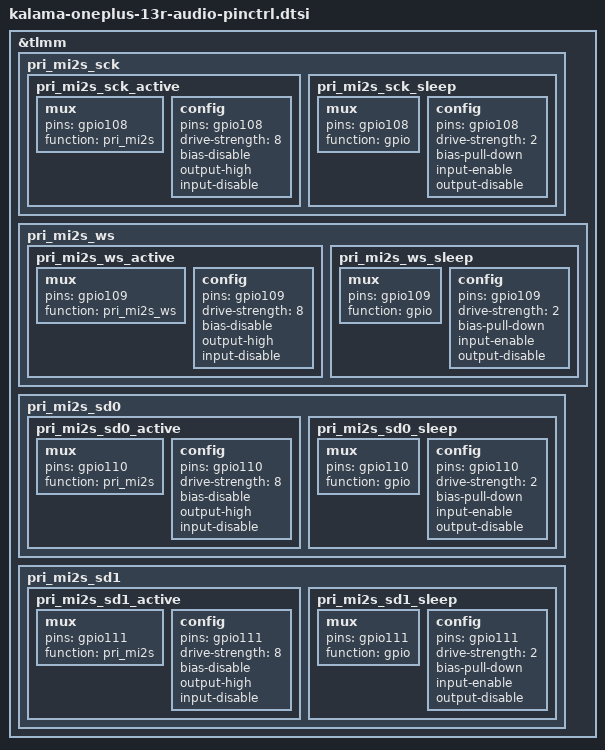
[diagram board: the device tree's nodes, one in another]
/*
 * Copyright (c) 2024, The LineageOS Project
 *
 * This program is free software; you can redistribute it and/or modify
 * it under the terms of the GNU General Public License version 2 and
 * only version 2 as published by the Free Software Foundation.
 *
 * This program is distributed in the hope that it will be useful,
 * but WITHOUT ANY WARRANTY; without even the implied warranty of
 * MERCHANTABILITY or FITNESS FOR A PARTICULAR PURPOSE.  See the
 * GNU General Public License for more details.
 */

&tlmm {
    pri_mi2s_sck {
        pri_mi2s_sck_active: pri_mi2s_sck_active {
            mux {
                pins = "gpio108";
                function = "pri_mi2s";
            };

            config {
                pins = "gpio108";
                drive-strength = <8>;
                bias-disable;
                output-high;
                input-disable;
            };
        };

        pri_mi2s_sck_sleep: pri_mi2s_sck_sleep {
            mux {
                pins = "gpio108";
                function = "gpio";
            };

            config {
                pins = "gpio108";
                drive-strength = <2>;
                bias-pull-down;
                input-enable;
                output-disable;
            };
        };
    };

    pri_mi2s_ws {
        pri_mi2s_ws_active: pri_mi2s_ws_active {
            mux {
                pins = "gpio109";
                function = "pri_mi2s_ws";
            };

            config {
                pins = "gpio109";
                drive-strength = <8>;
                bias-disable;
                output-high;
                input-disable;
            };
        };

        pri_mi2s_ws_sleep: pri_mi2s_ws_sleep {
            mux {
                pins = "gpio109";
                function = "gpio";
            };

            config {
                pins = "gpio109";
                drive-strength = <2>;
                bias-pull-down;
                input-enable;
                output-disable;
            };
        };
    };

    pri_mi2s_sd0 {
        pri_mi2s_sd0_active: pri_mi2s_sd0_active {
            mux {
                pins = "gpio110";
                function = "pri_mi2s";
            };

            config {
                pins = "gpio110";
                drive-strength = <8>;
                bias-disable;
                output-high;
                input-disable;
            };
        };

        pri_mi2s_sd0_sleep: pri_mi2s_sd0_sleep {
            mux {
                pins = "gpio110";
                function = "gpio";
            };

            config {
                pins = "gpio110";
                drive-strength = <2>;
                bias-pull-down;
                input-enable;
                output-disable;
            };
        };
    };

    pri_mi2s_sd1 {
        pri_mi2s_sd1_active: pri_mi2s_sd1_active {
            mux {
                pins = "gpio111";
                function = "pri_mi2s";
            };

            config {
                pins = "gpio111";
                drive-strength = <8>;
                bias-disable;
                output-high;
                input-disable;
            };
        };

        pri_mi2s_sd1_sleep: pri_mi2s_sd1_sleep {
            mux {
                pins = "gpio111";
                function = "gpio";
            };

            config {
                pins = "gpio111";
                drive-strength = <2>;
                bias-pull-down;
                input-enable;
                output-disable;
            };
        };
    };
}; 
